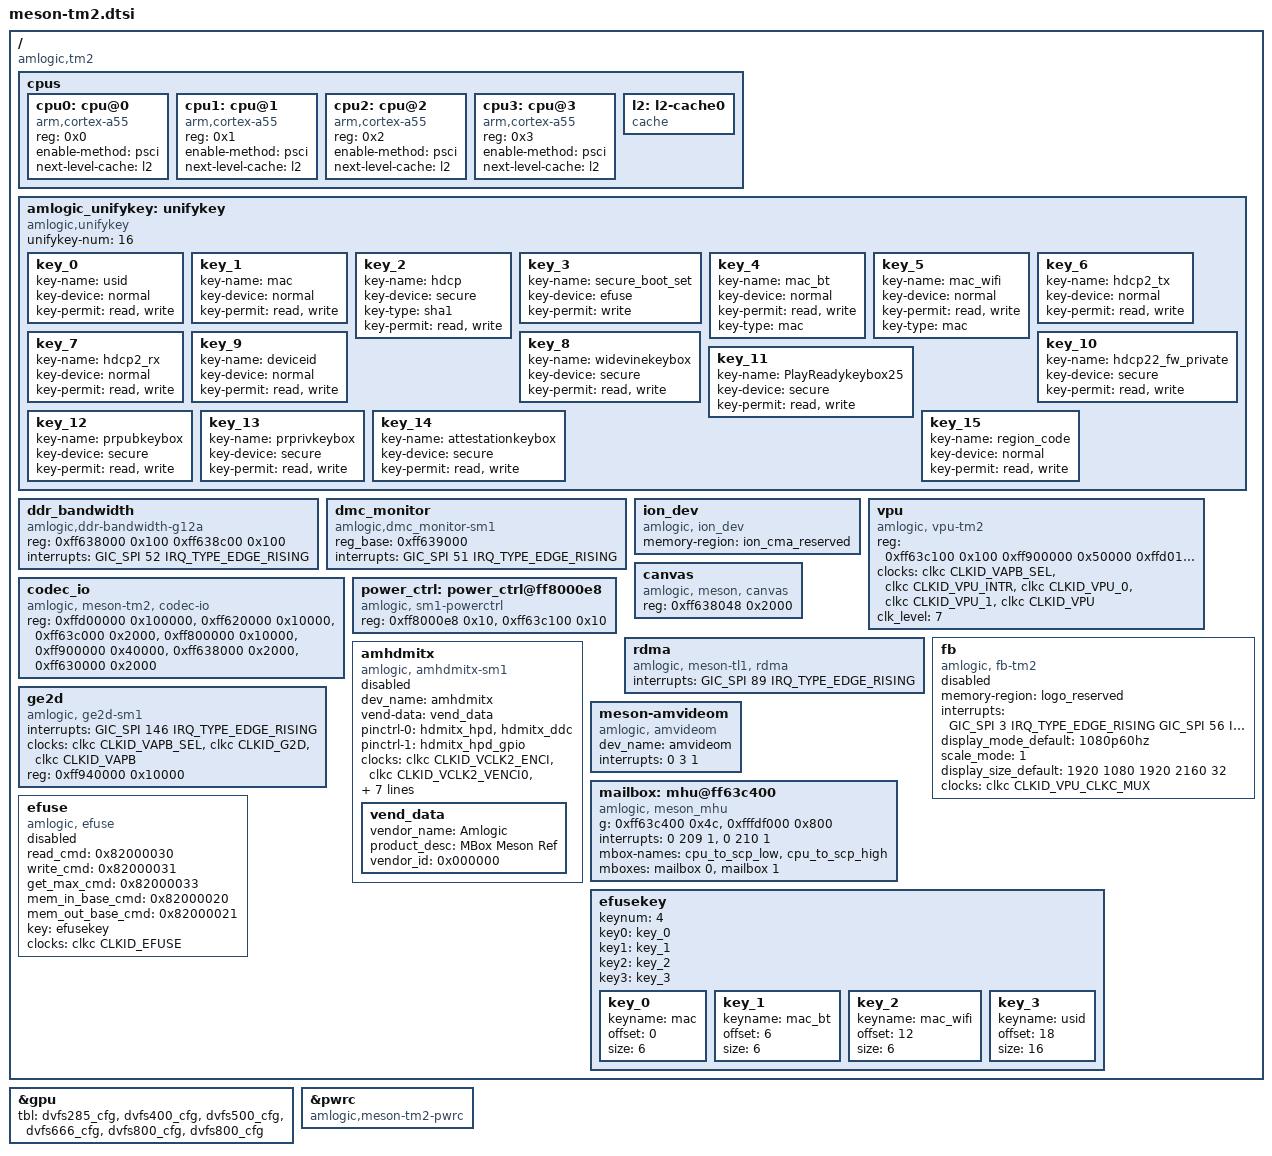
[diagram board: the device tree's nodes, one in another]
// SPDX-License-Identifier: (GPL-2.0+ OR MIT)
/*
 * Copyright (c) 2019 BayLibre, SAS
 * Author: Neil Armstrong <narmstrong@baylibre.com>
 */

#include "meson-tm-common.dtsi"

/ {
	compatible = "amlogic,tm2";

	cpus {
		#address-cells = <0x1>;
		#size-cells = <0x0>;

		cpu0: cpu@0 {
			device_type = "cpu";
			compatible = "arm,cortex-a55";
			reg = <0x0>;
			enable-method = "psci";
			next-level-cache = <&l2>;
		};

		cpu1: cpu@1 {
			device_type = "cpu";
			compatible = "arm,cortex-a55";
			reg = <0x1>;
			enable-method = "psci";
			next-level-cache = <&l2>;
		};

		cpu2: cpu@2 {
			device_type = "cpu";
			compatible = "arm,cortex-a55";
			reg = <0x2>;
			enable-method = "psci";
			next-level-cache = <&l2>;
		};

		cpu3: cpu@3 {
			device_type = "cpu";
			compatible = "arm,cortex-a55";
			reg = <0x3>;
			enable-method = "psci";
			next-level-cache = <&l2>;
		};

		l2: l2-cache0 {
			compatible = "cache";
		};
	};

	amlogic_unifykey: unifykey{
		compatible = "amlogic,unifykey";
		status = "okay";

		unifykey-num = <16>;

		key_0{
			key-name = "usid";
			key-device = "normal";
			key-permit = "read","write";
		};
		key_1{
			key-name = "mac";
			key-device = "normal";
			key-permit = "read","write";
		};
		key_2{
			key-name = "hdcp";
			key-device = "secure";
			key-type = "sha1";
			key-permit = "read","write";
		};
		key_3{
			key-name = "secure_boot_set";
			key-device = "efuse";
			key-permit = "write";
		};
		key_4{
			key-name = "mac_bt";
			key-device = "normal";
			key-permit = "read","write";
			key-type  = "mac";
		};
		key_5{
			key-name = "mac_wifi";
			key-device = "normal";
			key-permit = "read","write";
			key-type = "mac";
		};
		key_6{
			key-name = "hdcp2_tx";
			key-device = "normal";
			key-permit = "read","write";
		};
		key_7{
			key-name = "hdcp2_rx";
			key-device = "normal";
			key-permit = "read","write";
		};
		key_8{
			key-name = "widevinekeybox";
			key-device = "secure";
			key-permit = "read","write";
		};
		key_9{
			key-name = "deviceid";
			key-device = "normal";
			key-permit = "read","write";
		};
		key_10{
			key-name = "hdcp22_fw_private";
			key-device = "secure";
			key-permit = "read","write";
		};
		key_11{
			key-name = "PlayReadykeybox25";
			key-device = "secure";
			key-permit = "read","write";
		};
		key_12{
			key-name = "prpubkeybox";// PlayReady
			key-device = "secure";
			key-permit = "read","write";
		};
		key_13{
			key-name = "prprivkeybox";// PlayReady
			key-device = "secure";
			key-permit = "read","write";
		};
		key_14{
			key-name = "attestationkeybox";// attestation key
			key-device = "secure";
			key-permit = "read","write";
		};
		key_15{
			key-name = "region_code";
			key-device = "normal";
			key-permit = "read","write";
		};
	};//End unifykey

	ddr_bandwidth {
		compatible = "amlogic,ddr-bandwidth-g12a";
		status = "okay";
		reg = <0xff638000 0x100
			0xff638c00 0x100>;
		interrupts = <GIC_SPI 52 IRQ_TYPE_EDGE_RISING>;
		interrupt-names = "ddr_bandwidth";
	};

	dmc_monitor {
		compatible = "amlogic,dmc_monitor-sm1";
		status = "okay";
		reg_base = <0xff639000>;
		interrupts = <GIC_SPI 51 IRQ_TYPE_EDGE_RISING>;
	};

	ion_dev {
		compatible = "amlogic, ion_dev";
		memory-region = <&ion_cma_reserved>;
	};

	vpu {
		compatible = "amlogic, vpu-tm2";
		status = "okay";
		reg =	<0xff63c100 0x100  /* hiu */
			 0xff900000 0x50000 /* vcbus */
			 0xffd01080 0x20    /* cbus */
			 0xff8000e8 0x2>;   /* aobus */
		clocks = <&clkc CLKID_VAPB_SEL>,
			<&clkc CLKID_VPU_INTR>,
			<&clkc CLKID_VPU_0>,
			<&clkc CLKID_VPU_1>,
			<&clkc CLKID_VPU>;
		clock-names =	"vapb_clk",
				"vpu_intr_gate",
				"vpu_clk0",
				"vpu_clk1",
				"vpu_clk";
		clk_level = <7>;
		/* 0: 100.0M    1: 166.7M    2: 200.0M    3: 250.0M */
		/* 4: 333.3M    5: 400.0M    6: 500.0M    7: 666.7M */
	};

	canvas: canvas {
		compatible = "amlogic, meson, canvas";
		status = "okay";
		reg = <0xff638048 0x2000>;
	};

	codec_io: codec_io {
		compatible = "amlogic, meson-tm2, codec-io";
		status = "okay";
		#address-cells=<1>;
		#size-cells=<1>;
		ranges;
		reg =	<0xffd00000 0x100000>,
			<0xff620000 0x10000>,
			<0xff63c000 0x2000>,
			<0xff800000 0x10000>,
			<0xff900000 0x40000>,
			<0xff638000 0x2000>,
			<0xff630000 0x2000>;
		reg-names = "cbus",
			    "dosbus",
			    "hiubus",
			    "aobus",
			    "vcbus",
			    "dmcbus",
			    "efusebus";
	};

	power_ctrl: power_ctrl@ff8000e8 {
		compatible = "amlogic, sm1-powerctrl";
		reg = <0xff8000e8 0x10>,
		<0xff63c100 0x10>;
	};

	rdma {
		compatible = "amlogic, meson-tl1, rdma";
		status = "okay";
		interrupts = <GIC_SPI 89 IRQ_TYPE_EDGE_RISING>;
		interrupt-names = "rdma";
	};

	fb: fb {
		compatible = "amlogic, fb-tm2";
		memory-region = <&logo_reserved>;
		status = "disabled";
		interrupts = <GIC_SPI 3 IRQ_TYPE_EDGE_RISING
			GIC_SPI 56 IRQ_TYPE_EDGE_RISING
			GIC_SPI 89 IRQ_TYPE_EDGE_RISING>;
		interrupt-names = "viu-vsync", "viu2-vsync", "rdma";
		/* uboot logo,fb0/fb1 memory size,if afbcd fb0=0x01851000*/
		display_mode_default = "1080p60hz";
		scale_mode = <1>;
		/** 0:VPU free scale 1:OSD free scale 2:OSD super scale */
		display_size_default = <1920 1080 1920 2160 32>;
		/*1920*1080*4*3 = 0x17BB000*/
		clocks = <&clkc CLKID_VPU_CLKC_MUX>;
		clock-names = "vpu_clkc";
	};

	amhdmitx: amhdmitx{
		compatible = "amlogic, amhdmitx-sm1";
		dev_name = "amhdmitx";
		status = "disabled";
		vend-data = <&vend_data>;
		pinctrl-names="default", "hdmitx_i2c";
		pinctrl-0=<&hdmitx_hpd &hdmitx_ddc>;
		pinctrl-1=<&hdmitx_hpd_gpio>;
		clocks = <&clkc CLKID_VCLK2_ENCI
			&clkc CLKID_VCLK2_VENCI0
			&clkc CLKID_VCLK2_VENCI1
			&clkc CLKID_VAPB_SEL
			&clkc CLKID_VPU>;
		clock-names = "venci_top_gate",
			"venci_0_gate",
			"venci_1_gate",
			"hdmi_vapb_clk",
			"hdmi_vpu_clk";
		interrupts = <0 7 IRQ_TYPE_EDGE_RISING>;
		interrupt-names = "hdmitx_hpd";
		/* HPD, 57 + 32 = 89; CEC, 151 + 32 = 183*/
		/* 0:M8B   1:GXBB 2:GXTVBB 3:GXL  4:GXM
		 * 5:TXL   6:TXLX 7:AXG    8:GXLX 9:TXHD
		 * 10:G12A 11:G12B 12:SM1  13:TM2
		 */
		ic_type = <13>;
		reg =	<0xffd00000 0x100000>,
			<0xff900000 0x40000>,
			<0xff63c000 0x2000>,
			<0xff670000 0x8000>,
			<0xff678000 0x4000>,
			<0xffe01000 0x100>;
		reg-names = "cbus",
			    "vcbus",
			    "hiubus",
			    "hdmitxsec",
			    "hdmitx",
			    "esm";
		vend_data: vend_data{ /* Should modified by Customer */
			vendor_name = "Amlogic"; /* Max Chars: 8 */
			product_desc = "MBox Meson Ref"; /* Max Chars: 16 */
			/* standards.ieee.org/develop/regauth/oui/oui.txt */
			vendor_id = <0x000000>;
		};
	};

	ge2d: ge2d {
		compatible = "amlogic, ge2d-sm1";
		status = "okay";
		interrupts = <GIC_SPI 146 IRQ_TYPE_EDGE_RISING>;
		interrupt-names = "ge2d";
		clocks = <&clkc CLKID_VAPB_SEL>,
			<&clkc CLKID_G2D>,
			<&clkc CLKID_VAPB>;
		clock-names = "clk_vapb_0",
			"clk_ge2d",
			"clk_ge2d_gate";
		reg = <0xff940000 0x10000>;
	};

	meson-amvideom {
		compatible = "amlogic, amvideom";
		dev_name = "amvideom";
		status = "okay";
		interrupts = <0 3 1>;
		interrupt-names = "vsync";
	};

	mailbox: mhu@ff63c400 {
		status = "okay";
		compatible = "amlogic, meson_mhu";
		g = <0xff63c400 0x4c>,   /* MHU registers */
		    <0xfffdf000 0x800>;   /* Payload area */
		interrupts = <0 209 1>,   /* low priority interrupt */
			     <0 210 1>;   /* high priority interrupt */
		#mbox-cells = <1>;
		mbox-names = "cpu_to_scp_low", "cpu_to_scp_high";
		mboxes = <&mailbox 0 &mailbox 1>;
	};

	efuse: efuse {
		compatible = "amlogic, efuse";
		read_cmd = <0x82000030>;
		write_cmd = <0x82000031>;
		get_max_cmd = <0x82000033>;
		mem_in_base_cmd = <0x82000020>;
		mem_out_base_cmd = <0x82000021>;
		key = <&efusekey>;
		clocks = <&clkc CLKID_EFUSE>;
		clock-names = "efuse_clk";
		status = "disabled";
	};

	efusekey: efusekey {
		keynum = <4>;
		key0 = <&key_0>;
		key1 = <&key_1>;
		key2 = <&key_2>;
		key3 = <&key_3>;

		key_0: key_0 {
			keyname = "mac";
			offset = <0>;
			size = <6>;
		};
		key_1: key_1 {
			keyname = "mac_bt";
			offset = <6>;
			size = <6>;
		};
		key_2: key_2 {
			keyname = "mac_wifi";
			offset = <12>;
			size = <6>;
		};
		key_3: key_3 {
			keyname = "usid";
			offset = <18>;
			size = <16>;
		};
	};
};

&gpu{
	tbl =  <&dvfs285_cfg
		&dvfs400_cfg
		&dvfs500_cfg
		&dvfs666_cfg
		&dvfs800_cfg
		&dvfs800_cfg>;
};

&pwrc {
	compatible = "amlogic,meson-tm2-pwrc";
};

/*
 *&usb2_phy_v2 {
 *	power-domains = <&pwrc PWRC_SM1_USB_ID>;
 *};
 *
 *&usb3_phy_v2 {
 *	power-domains = <&pwrc PWRC_SM1_PCIE_ID>;
 *};
 */
